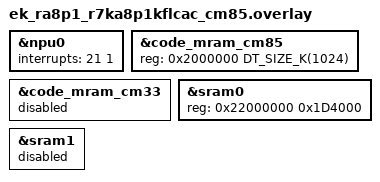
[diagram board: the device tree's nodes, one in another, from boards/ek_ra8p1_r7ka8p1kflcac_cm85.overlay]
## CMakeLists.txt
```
cmake_minimum_required(VERSION 3.20.0)

find_package(Zephyr REQUIRED HINTS $ENV{ZEPHYR_BASE})

project(zephyr_face_detection C CXX)

target_include_directories(app PRIVATE
    ${CMAKE_CURRENT_SOURCE_DIR}/ai_application
    ${CMAKE_CURRENT_SOURCE_DIR}/ai_application/common
    ${CMAKE_CURRENT_SOURCE_DIR}/ai_application/face_detection
    ${CMAKE_CURRENT_SOURCE_DIR}/ai_application/face_detection/model
    ${CMAKE_CURRENT_SOURCE_DIR}/src
)

FILE(GLOB app_sources src/*.c src/*.cc)
FILE(GLOB ai_common ai_application/common/*.c ai_application/common/*.cc)
FILE(GLOB ai_face_detection ai_application/face_detection/*.c ai_application/face_detection/*.cc)

target_sources(app PRIVATE
    ${app_sources}
    ${ai_common}
    ${ai_face_detection}
)
```

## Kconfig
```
mainmenu "Video capture to LVGL sample application"

menu "Video capture configuration"

config VIDEO_WIDTH
	int "Define the width of the video"
	default 640

config VIDEO_HEIGHT
	int "Define the height of the video"
	default 480

endmenu

menu "Screen Configuration"

config SCREEN_ORIENTATION
	int "Screen orientation"
	default 90
	help
	  Orientation of the screen in degrees (0, 90, 180, 270).

config SCREEN_WIDTH
	int "Screen width"
	default 854
	help
	  Width of the screen in pixels.

config SCREEN_HEIGHT
	int "Screen height"
	default 480
	help
	  Height of the screen in pixels.
endmenu

menu "AI Configuration"

config AI_INPUT_WIDTH
	int "AI input image width"
	default 192
	help
	  Width of the input image for AI model.

config AI_INPUT_HEIGHT
	int "AI input image height"
	default 192
	help
	  Height of the input image for AI model.

config AI_INPUT_BYTE_PER_PIXEL
	int "AI input image bytes per pixel"
	default 1
	help
	  Bytes per pixel (1 = grayscale, 3 = RGB).

config AI_MAX_DETECTION_NUM
	int "Maximum number of detections"
	default 20
	help
	  Maximum number of faces (or objects) the model can detect.

endmenu

menu "Thread Stack Sizes"

config AI_THREAD_STACK_SIZE
	int "AI task stack size"
	default 16384
	help
	  Stack size for the AI processing task.

config CAMERA_THREAD_STACK_SIZE
	int "Camera task stack size"
	default 4096
	help
	  Stack size for the camera capture task.

config DISPLAY_THREAD_STACK_SIZE
	int "Display task stack size"
	default 4096
	help
	  Stack size for the display task.

endmenu

source "Kconfig.zephyr"
```

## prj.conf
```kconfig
CONFIG_CPP=y
CONFIG_STD_CPP17=y
CONFIG_TENSORFLOW_LITE_MICRO=y
CONFIG_ETHOS_U=y
CONFIG_MAIN_STACK_SIZE=4096
CONFIG_HEAP_MEM_POOL_SIZE=16384
CONFIG_LOG=y
CONFIG_CMSIS_DSP=y
CONFIG_VIDEO=y
CONFIG_DISPLAY=y
CONFIG_DISPLAY_LOG_LEVEL_ERR=y
CONFIG_LVGL=y
CONFIG_LV_CONF_MINIMAL=y
CONFIG_LV_USE_IMAGE=y
CONFIG_LV_Z_MEM_POOL_SIZE=58368
CONFIG_LV_USE_PERF_MONITOR=y
CONFIG_LV_USE_DROPDOWN=y
CONFIG_LV_USE_SYSMON=y
CONFIG_LV_USE_CANVAS=y
CONFIG_LV_FONT_MONTSERRAT_16=y
```

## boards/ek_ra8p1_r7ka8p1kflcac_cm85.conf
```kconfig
CONFIG_VIDEO_BUFFER_POOL_SZ_MAX=615000
CONFIG_VIDEO_BUFFER_POOL_NUM_MAX=2
CONFIG_LV_USE_DRAW_DAVE2D=y
CONFIG_RENESAS_DAVE2D_RUNTIME_HEAP_SIZE=24876
CONFIG_DCACHE=y
CONFIG_CACHE_MANAGEMENT=y 
```

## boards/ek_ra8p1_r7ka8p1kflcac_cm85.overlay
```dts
/*
 * Copyright (c) 2025 Renesas Electronics Corporation
 * SPDX-License-Identifier: Apache-2.0
 */

&npu0 {
	interrupts = <21 1>;
	interrupt-names = "npu-irq";
	status = "okay";
};

&code_mram_cm85 {
	reg = <0x2000000 DT_SIZE_K(1024)>;
};

&code_mram_cm33 {
	status = "disabled";
};

&sram0 {
	reg = <0x22000000 0x1D4000>;
};

&sram1 {
	status = "disabled";
};
```

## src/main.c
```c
#include <zephyr/logging/log.h>

#include "ai_processing.h"
#include "camera.h"
#include "display.h"
#include "common_util.h"

K_THREAD_STACK_DEFINE(camera_stack_area, CONFIG_CAMERA_THREAD_STACK_SIZE);
K_THREAD_STACK_DEFINE(display_stack_area, CONFIG_DISPLAY_THREAD_STACK_SIZE);
K_THREAD_STACK_DEFINE(ai_stack_area, CONFIG_AI_THREAD_STACK_SIZE);

LOG_MODULE_REGISTER(main, CONFIG_LOG_DEFAULT_LEVEL);

static struct k_thread camera_thread;
static struct k_thread display_thread;
static struct k_thread ai_thread;

K_MSGQ_DEFINE(display_frame_msgq, sizeof(camera_frame_msg_t), DISPLAY_QUEUE_DEPTH, 4);
K_MSGQ_DEFINE(ai_input_msgq, sizeof(ai_input_msg_t), AI_INPUT_QUEUE_DEPTH, 4);
K_MSGQ_DEFINE(ai_result_msgq, sizeof(void *), AI_RESULT_QUEUE_DEPTH, 4);

int main(void)
{
	LOG_INF("Zephyr Face Detection sample app!");

	int ret;
	ret = camera_init();
	if (ret != 0) {
		LOG_ERR("Camera initialization failed");
		return 0;
	}

	ret = display_init();
	if (ret != 0) {
		LOG_ERR("Display initialization failed");
		return 0;
	}

	k_thread_create(&camera_thread, camera_stack_area, K_THREAD_STACK_SIZEOF(camera_stack_area),
			camera_task, &display_frame_msgq, &ai_input_msgq, NULL,
			CAMERA_THREAD_PRIORITY, 0, K_NO_WAIT);

	k_thread_create(&ai_thread, ai_stack_area, K_THREAD_STACK_SIZEOF(ai_stack_area), ai_task,
			&ai_input_msgq, &ai_result_msgq, NULL, AI_THREAD_PRIORITY, 0, K_NO_WAIT);

	k_thread_create(&display_thread, display_stack_area,
			K_THREAD_STACK_SIZEOF(display_stack_area), display_task,
			&display_frame_msgq, &ai_result_msgq, NULL, DISPLAY_THREAD_PRIORITY, 0,
			K_NO_WAIT);

	k_sleep(K_FOREVER);

	return 0;
}
```

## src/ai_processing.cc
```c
#include <zephyr/logging/log.h>
#include <zephyr/drivers/video.h>

#include "inference_process.hpp"
#include "common_util.h"
#include "ai_processing.h"
#include "model_data.h"

LOG_MODULE_REGISTER(ai_processing, CONFIG_LOG_DEFAULT_LEVEL);

using namespace InferenceProcess;

namespace
{
TENSOR_ARENA_ATTR uint8_t inferenceProcessTensorArena[TENSOR_ARENA_SIZE];

std::array<st_ai_detection_point_t, CONFIG_AI_MAX_DETECTION_NUM> g_ai_detection;

static InferenceProcess::InferenceProcess inference(inferenceProcessTensorArena, TENSOR_ARENA_SIZE);
} // namespace

void ai_task(void *arg1, void *arg2, void *arg3)
{
	ARG_UNUSED(arg3);

	struct k_msgq *ai_input_msgq = (struct k_msgq *)arg1;
	struct k_msgq *ai_result_msgq = (struct k_msgq *)arg2;
	st_ai_detection_point_t *p_det;
	ai_input_msg_t ai_input_msg;

	for (;;) {
		if (k_msgq_get(ai_input_msgq, &ai_input_msg, K_FOREVER) == 0) {
			InferenceProcess::InferenceJob job(
				"FaceDetection", {DataPtr(model_data, sizeof(model_data))},
				{DataPtr(ai_input_msg.data, ai_input_msg.size)});

			inference.runJob(job);

			auto &results = job.getResults();

			g_ai_detection.fill({0, 0, 0, 0});

			for (uint16_t i = 0; i < results.size(); ++i) {
				g_ai_detection[i].m_x = results[i].m_x0;
				g_ai_detection[i].m_y = results[i].m_y0;
				g_ai_detection[i].m_w = results[i].m_w;
				g_ai_detection[i].m_h = results[i].m_h;
				LOG_INF("x=%d, y=%d, w=%d, h=%d\n", g_ai_detection[i].m_x,
					g_ai_detection[i].m_y, g_ai_detection[i].m_w,
					g_ai_detection[i].m_h);
			}

			p_det = &g_ai_detection[0];

			k_msgq_put(ai_result_msgq, &p_det, K_NO_WAIT);
		}
	}
}
```

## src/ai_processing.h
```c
#ifndef _AI_PROCESSING_H_
#define _AI_PROCESSING_H_

#ifdef __cplusplus
extern "C" {
#endif

void ai_task(void *, void *, void *);

#ifdef __cplusplus
}
#endif

#endif
```

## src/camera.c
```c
#include <zephyr/logging/log.h>
#include <zephyr/drivers/video-controls.h>
#include <zephyr/drivers/video.h>

#include "camera.h"
#include "common_util.h"
#include "ai_processing.h"

LOG_MODULE_REGISTER(camera, CONFIG_LOG_DEFAULT_LEVEL);

static int8_t model_buffer_int8[CONFIG_AI_INPUT_WIDTH * CONFIG_AI_INPUT_HEIGHT *
				CONFIG_AI_INPUT_BYTE_PER_PIXEL] __attribute__((aligned(8)));
const struct device *video_dev;
static struct video_buffer *buffers[2];
static enum video_buf_type type = VIDEO_BUF_TYPE_OUTPUT;

static void set_control(const struct device *dev, uint32_t id, int32_t value)
{
	struct video_control ctrl = {
		.id = id,
		.val = value,
	};
	int ret = video_set_ctrl(dev, &ctrl);
	LOG_INF("Set CID=0x%x val=%d ret=%d", id, value, ret);
}

void video_set_balanced_colors(const struct device *dev)
{
	set_control(dev, VIDEO_CID_BRIGHTNESS, 3);
}

int camera_init(void)
{
	struct video_format fmt;
	struct video_caps caps;
	size_t bsize;
	int ret;

	video_dev = DEVICE_DT_GET(DT_CHOSEN(zephyr_camera));

	ret = device_is_ready(video_dev);
	if (ret < 0) {
		LOG_ERR("%s device is not ready", video_dev->name);
		return ret;
	}

	LOG_INF("- Device name: %s", video_dev->name);

	/* Get capabilities */
	caps.type = type;
	ret = video_get_caps(video_dev, &caps);
	if (ret < 0) {
		LOG_ERR("Unable to retrieve video capabilities");
		return ret;
	}

	/* Get default/native format */
	fmt.type = type;
	ret = video_get_format(video_dev, &fmt);
	if (ret < 0) {
		LOG_ERR("Unable to retrieve video format");
		return ret;
	}

	fmt.width = CONFIG_VIDEO_WIDTH;
	fmt.height = CONFIG_VIDEO_HEIGHT;
	fmt.pixelformat = VIDEO_PIX_FMT_RGB565;
	ret = video_set_format(video_dev, &fmt);
	if (ret < 0) {
		LOG_ERR("Unable to set up video format %d", ret);
		return ret;
	}

	/* Size to allocate for each buffer */
	bsize = fmt.pitch * fmt.height;

	/* Alloc video buffers and enqueue for capture */
	for (int i = 0; i < ARRAY_SIZE(buffers); i++) {
		buffers[i] = video_buffer_aligned_alloc(bsize, CONFIG_VIDEO_BUFFER_POOL_ALIGN,
							K_FOREVER);
		if (buffers[i] == NULL) {
			LOG_ERR("Unable to alloc video buffer");
			return -1;
		}
		buffers[i]->type = type;
		video_enqueue(video_dev, buffers[i]);
	}

	video_set_balanced_colors(video_dev);

	/* Start video capture */
	ret = video_stream_start(video_dev, type);
	if (ret < 0) {
		LOG_ERR("Unable to start capture (interface)");
		return ret;
	}

	LOG_INF("- Camera initialized and capture started");
	return 0;
}

int image_rgb565_to_int8(const void *p_input_image_buff, void *p_output_image_buff,
			 uint16_t in_width, uint16_t in_height, uint16_t out_width,
			 uint16_t out_height)
{
	if ((p_input_image_buff == NULL) || (p_output_image_buff == NULL)) {
		return -EINVAL;
	}

	if (in_width < in_height) {
		return -EINVAL;
	}

	const uint16_t *p_input = (const uint16_t *)p_input_image_buff;
	int8_t *p_output = (int8_t *)p_output_image_buff;

	const uint32_t crop_offset = CROP_OFFSET(in_width, in_height);

	for (uint32_t y = 0; y < out_height; y++) {
		uint32_t y_offset = in_width * ((in_height * y) / out_height);
		const uint16_t *p_input_base = p_input + crop_offset + y_offset;

		for (uint32_t x = 0; x < out_width; x++) {
			uint16_t input_pixel = *(p_input_base + ((in_height * x) / out_width));
			*p_output++ = RGB565_TO_INT8_GRAY(input_pixel);
		}
	}

	return 0;
}

void camera_task(void *arg1, void *arg2, void *arg3)
{
	ARG_UNUSED(arg3);

	struct video_buffer *vbuf = &(struct video_buffer){};
	int err;
	struct k_msgq *display_frame_msgq = (struct k_msgq *)arg1;
	struct k_msgq *ai_input_msgq = (struct k_msgq *)arg2;
	ai_input_msg_t ai_input_msg;
	camera_frame_msg_t camera_frame_msg;
	vbuf->type = type;

	while (1) {
		err = video_dequeue(video_dev, &vbuf, K_FOREVER);
		if (err) {
			LOG_ERR("Unable to dequeue video buf");
			continue;
		}

		if (k_msgq_num_free_get(ai_input_msgq) > 0) {
			image_rgb565_to_int8(&vbuf->buffer[0], &model_buffer_int8[0],
					     CONFIG_VIDEO_WIDTH, CONFIG_VIDEO_HEIGHT,
					     CONFIG_AI_INPUT_WIDTH, CONFIG_AI_INPUT_HEIGHT);
			ai_input_msg.size = sizeof(model_buffer_int8);
			ai_input_msg.data = &model_buffer_int8[0];
			err = k_msgq_put(ai_input_msgq, &ai_input_msg, K_NO_WAIT);
			if (err) {
				LOG_ERR("Failed to put frame into AI input queue");
			}
		}

        camera_frame_msg.vbuf = vbuf;
        camera_frame_msg.video_dev = (struct device *)video_dev;

		err = k_msgq_put(display_frame_msgq, &camera_frame_msg, K_FOREVER);
		if (err) {
			LOG_ERR("Failed to put frame into display queue");
		}
	}
}
```

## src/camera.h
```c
#ifndef _CAMERA_HANDLE_H_
#define _CAMERA_HANDLE_H_

int camera_init(void);

void camera_task(void *, void *, void *);

#endif
```

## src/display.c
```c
#include <zephyr/logging/log.h>
#include <zephyr/drivers/display.h>
#include <zephyr/drivers/video.h>

#include "display.h"
#include "common_util.h"

LOG_MODULE_REGISTER(app_display, CONFIG_LOG_DEFAULT_LEVEL);

static const struct device *display_dev;
static lv_img_dsc_t video_img;
static lv_obj_t *screen, *bg, *face_count_label;
static lv_obj_t *bbox_rect[CONFIG_AI_MAX_DETECTION_NUM];

static void draw_ai_bboxes_lvgl(st_ai_detection_point_t *ai_detection, uint16_t max_detection_num)
{
	int ai_w = CONFIG_AI_INPUT_WIDTH;
	int ai_h = CONFIG_AI_INPUT_HEIGHT;
	int ai_display_sides = CONFIG_SCREEN_WIDTH < CONFIG_SCREEN_HEIGHT ? CONFIG_SCREEN_WIDTH
									  : CONFIG_SCREEN_HEIGHT;
	int face_count = 0;

	// Loop over all detected faces and update bounding boxes
	for (int i = 0; i < max_detection_num; i++) {
		signed short x = ai_detection[i].m_x;
		signed short y = ai_detection[i].m_y;
		signed short w = ai_detection[i].m_w;
		signed short h = ai_detection[i].m_h;

		if (w > 0 && h > 0) {
			face_count++;
			int x_ai = (y * ai_display_sides) / ai_w;
			int y_ai = (x * ai_display_sides) / ai_h;
			int w_ai = (h * ai_display_sides) / ai_w;
			int h_ai = (w * ai_display_sides) / ai_h;

			lv_obj_set_pos(bbox_rect[i], ai_display_sides - x_ai - w_ai, y_ai + ((CONFIG_SCREEN_WIDTH - ai_display_sides) / 2));
			lv_obj_set_size(bbox_rect[i], w_ai, h_ai);
		} else {
			lv_obj_set_size(bbox_rect[i], 0, 0);
		}
	}

	lv_label_set_text_fmt(face_count_label, "Detected Faces: %d", face_count);
}

int display_init(void)
{
	display_dev = DEVICE_DT_GET(DT_CHOSEN(zephyr_display));
	if (!device_is_ready(display_dev)) {
		LOG_ERR("Display device not ready");
		return -1;
	}

	display_blanking_off(display_dev);

	video_img.header.w = CONFIG_VIDEO_WIDTH;
	video_img.header.h = CONFIG_VIDEO_HEIGHT;
	video_img.data_size = CONFIG_VIDEO_WIDTH * CONFIG_VIDEO_HEIGHT * sizeof(lv_color_t);
	video_img.header.cf = LV_COLOR_FORMAT_NATIVE;

	bg = lv_obj_create(lv_scr_act());
	lv_obj_set_size(bg, CONFIG_SCREEN_HEIGHT, CONFIG_SCREEN_WIDTH);
	lv_obj_set_style_bg_color(bg, BACKGROUND_COLOR, 0);
	lv_obj_set_style_bg_opa(bg, LV_OPA_COVER, 0);
	lv_obj_align(bg, LV_ALIGN_TOP_MID, 0, 0);

	lv_task_handler();

	screen = lv_img_create(lv_scr_act());
	lv_img_set_src(screen, &video_img);
	lv_obj_align(screen, LV_ALIGN_CENTER, 0, 0);

	// Create and position the label for the face count at the bottom center of the screen
	face_count_label = lv_label_create(lv_scr_act());
	lv_obj_set_style_bg_color(face_count_label, lv_color_black(), 0);
	lv_obj_set_style_text_color(face_count_label, lv_color_white(), 0);
	lv_obj_set_style_text_font(face_count_label, &lv_font_montserrat_16, 0);
	lv_obj_set_style_bg_opa(face_count_label, LV_OPA_50, 0);
	lv_obj_set_style_pad_all(face_count_label, 6, 0);
	lv_obj_set_style_radius(face_count_label, 6, 0);

	lv_label_set_text(face_count_label, "Faces: 0");
	lv_obj_align(face_count_label, LV_ALIGN_BOTTOM_MID, 0, -10); // 10 pixels above the bottom edge

	for (int i = 0; i < CONFIG_AI_MAX_DETECTION_NUM; i++) {
		bbox_rect[i] = lv_obj_create(lv_scr_act());
		lv_obj_set_size(bbox_rect[i], 0, 0);
		lv_obj_set_style_border_width(bbox_rect[i], 5, 0);
		lv_obj_set_style_border_color(bbox_rect[i], BBOX_COLOR, 0);
		lv_obj_set_style_bg_opa(bbox_rect[i], LV_OPA_TRANSP, 0);
		lv_obj_align(bbox_rect[i], LV_ALIGN_TOP_LEFT, 0, 0);
	}

	LOG_INF("- Display initialized");
	return 0;
}

void display_task(void *arg1, void *arg2, void *arg3)
{
	ARG_UNUSED(arg3);

	int err;
	struct k_msgq *display_frame_msgq = (struct k_msgq *)arg1;
	struct k_msgq *ai_result_msgq = (struct k_msgq *)arg2;
	static st_ai_detection_point_t *ai_detection;
	camera_frame_msg_t camera_frame_msg;

	while (1) {
		if (k_msgq_get(display_frame_msgq, &camera_frame_msg, K_FOREVER) != 0) {
			continue;
		}
		video_img.data = (const uint8_t *)camera_frame_msg.vbuf->buffer;

		lv_img_set_src(screen, &video_img);
		lv_img_set_angle(screen, CONFIG_SCREEN_ORIENTATION * 10);

		if (k_msgq_get(ai_result_msgq, &ai_detection, K_NO_WAIT) == 0) {
			draw_ai_bboxes_lvgl(ai_detection, CONFIG_AI_MAX_DETECTION_NUM);
		}

		lv_task_handler();

		err = video_enqueue(camera_frame_msg.video_dev, camera_frame_msg.vbuf);
		if (err) {
			LOG_ERR("Unable to requeue video buf");
		}
	}
}
```

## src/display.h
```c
#ifndef _DISPLAY_HANDLE_H_
#define _DISPLAY_HANDLE_H_

#include <lvgl.h>

#ifdef __cplusplus
extern "C" {
#endif

#define BACKGROUND_COLOR lv_color_make(0x00, 0x33, 0x99)
#define BBOX_COLOR       lv_color_make(0x00, 0xFF, 0x00)

int display_init(void);

void display_task(void *, void *, void *);

#ifdef __cplusplus
}
#endif

#endif
```
